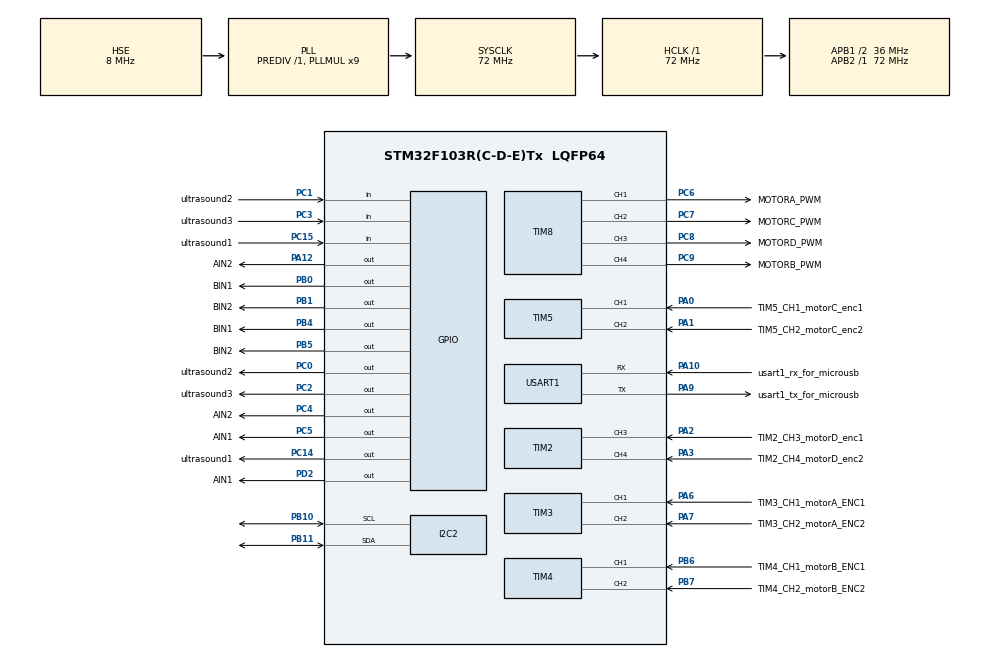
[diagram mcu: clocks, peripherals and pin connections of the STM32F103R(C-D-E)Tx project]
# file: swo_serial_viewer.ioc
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Mcu.Family=STM32F1
Mcu.Name=STM32F103R(C-D-E)Tx
Mcu.Package=LQFP64
NVIC.PriorityGroup=NVIC_PRIORITYGROUP_4
PA0-WKUP.GPIO_Label=TIM5_CH1_motorC_enc1
PA0-WKUP.Signal=S_TIM5_CH1
PA1.GPIO_Label=TIM5_CH2_motorC_enc2
PA1.Signal=S_TIM5_CH2
PA10.GPIO_Label=usart1_rx_for_microusb
PA10.Mode=Asynchronous
PA10.Signal=USART1_RX
PA12.GPIO_Label=AIN2
PA12.Signal=GPIO_Output
PA13.Mode=JTAG_4_pins
PA13.Signal=SYS_JTMS-SWDIO
PA14.Mode=JTAG_4_pins
PA14.Signal=SYS_JTCK-SWCLK
PA15.Mode=JTAG_4_pins
PA15.Signal=SYS_JTDI
PA2.GPIO_Label=TIM2_CH3_motorD_enc1
PA2.Signal=S_TIM2_CH3
PA3.GPIO_Label=TIM2_CH4_motorD_enc2
PA3.Signal=S_TIM2_CH4
PA6.GPIO_Label=TIM3_CH1_motorA_ENC1
PA6.Signal=S_TIM3_CH1
PA7.GPIO_Label=TIM3_CH2_motorA_ENC2
PA7.Signal=S_TIM3_CH2
PA9.GPIO_Label=usart1_tx_for_microusb
PA9.Mode=Asynchronous
PA9.Signal=USART1_TX
PB0.GPIO_Label=BIN1
PB0.Signal=GPIO_Output
PB1.GPIO_Label=BIN2
PB1.Signal=GPIO_Output
PB10.Mode=I2C
PB10.Signal=I2C2_SCL
PB11.Mode=I2C
PB11.Signal=I2C2_SDA
PB3.Mode=JTAG_4_pins
PB3.Signal=SYS_JTDO-TRACESWO
PB4.GPIO_Label=BIN1
PB4.Signal=GPIO_Output
PB5.GPIO_Label=BIN2
PB5.Signal=GPIO_Output
PB6.GPIO_Label=TIM4_CH1_motorB_ENC1
PB6.Signal=S_TIM4_CH1
PB7.GPIO_Label=TIM4_CH2_motorB_ENC2
PB7.Signal=S_TIM4_CH2
PC0.GPIO_Label=ultrasound2
PC0.Signal=GPIO_Output
PC1.GPIO_Label=ultrasound2
PC1.Signal=GPIO_Input
PC14-OSC32_IN.GPIO_Label=ultrasound1
PC14-OSC32_IN.Signal=GPIO_Output
PC15-OSC32_OUT.GPIO_Label=ultrasound1
PC15-OSC32_OUT.Signal=GPIO_Input
PC2.GPIO_Label=ultrasound3
PC2.Signal=GPIO_Output
PC3.GPIO_Label=ultrasound3
PC3.Signal=GPIO_Input
PC4.GPIO_Label=AIN2
PC4.Signal=GPIO_Output
PC5.GPIO_Label=AIN1
PC5.Signal=GPIO_Output
PC6.GPIO_Label=MOTORA_PWM
PC6.Signal=S_TIM8_CH1
PC7.GPIO_Label=MOTORC_PWM
PC7.Signal=S_TIM8_CH2
PC8.GPIO_Label=MOTORD_PWM
PC8.Signal=S_TIM8_CH3
PC9.GPIO_Label=MOTORB_PWM
PC9.Signal=S_TIM8_CH4
PD0-OSC_IN.Mode=HSE-External-Oscillator
PD0-OSC_IN.Signal=RCC_OSC_IN
PD1-OSC_OUT.Mode=HSE-External-Oscillator
PD1-OSC_OUT.Signal=RCC_OSC_OUT
PD2.GPIO_Label=AIN1
PD2.Signal=GPIO_Output
ProjectManager.HeapSize=0x200
ProjectManager.StackSize=0x400
ProjectManager.TargetToolchain=STM32CubeIDE
RCC.AHBFreq_Value=72000000
RCC.APB1CLKDivider=RCC_HCLK_DIV2
RCC.APB1Freq_Value=36000000
RCC.APB1TimFreq_Value=72000000
RCC.APB2Freq_Value=72000000
RCC.APB2TimFreq_Value=72000000
RCC.HCLKFreq_Value=72000000
RCC.PLLMUL=RCC_PLL_MUL9
RCC.PLLSourceVirtual=RCC_PLLSOURCE_HSE
RCC.SYSCLKFreq_VALUE=72000000
RCC.SYSCLKSource=RCC_SYSCLKSOURCE_PLLCLK
RCC.USBFreq_Value=72000000
SH.S_TIM2_CH3.0=TIM2_CH3,Input_Capture3_from_TI3
SH.S_TIM2_CH4.0=TIM2_CH4,Input_Capture4_from_TI4
SH.S_TIM3_CH1.0=TIM3_CH1,Input_Capture1_from_TI1
SH.S_TIM3_CH2.0=TIM3_CH2,Input_Capture2_from_TI2
SH.S_TIM4_CH1.0=TIM4_CH1,Input_Capture1_from_TI1
SH.S_TIM4_CH2.0=TIM4_CH2,Input_Capture2_from_TI2
SH.S_TIM5_CH1.0=TIM5_CH1,Input_Capture1_from_TI1
SH.S_TIM5_CH2.0=TIM5_CH2,Input_Capture2_from_TI2
SH.S_TIM8_CH1.0=TIM8_CH1,Output Compare1 CH1
SH.S_TIM8_CH2.0=TIM8_CH2,Output Compare2 CH2
SH.S_TIM8_CH3.0=TIM8_CH3,Output Compare3 CH3
SH.S_TIM8_CH4.0=TIM8_CH4,Output Compare4 CH4
TIM2.Channel-Input_Capture3_from_TI3=TIM_CHANNEL_3
TIM2.Channel-Input_Capture4_from_TI4=TIM_CHANNEL_4
TIM3.Channel-Input_Capture1_from_TI1=TIM_CHANNEL_1
TIM3.Channel-Input_Capture2_from_TI2=TIM_CHANNEL_2
TIM4.Channel-Input_Capture1_from_TI1=TIM_CHANNEL_1
TIM4.Channel-Input_Capture2_from_TI2=TIM_CHANNEL_2
TIM5.Channel-Input_Capture1_from_TI1=TIM_CHANNEL_1
TIM5.Channel-Input_Capture2_from_TI2=TIM_CHANNEL_2
TIM8.Channel-Output\ Compare1\ CH1=TIM_CHANNEL_1
TIM8.Channel-Output\ Compare2\ CH2=TIM_CHANNEL_2
TIM8.Channel-Output\ Compare3\ CH3=TIM_CHANNEL_3
TIM8.Channel-Output\ Compare4\ CH4=TIM_CHANNEL_4
USART1.VirtualMode=VM_ASYNC
board=custom

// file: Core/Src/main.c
/* USER CODE BEGIN Header */
/**
  ******************************************************************************
  * @file           : main.c
  * @brief          : Main program body
  ******************************************************************************
  * @attention
  *
  * <h2><center>&copy; Copyright (c) 2021 STMicroelectronics.
  * All rights reserved.</center></h2>
  *
  * This software component is licensed by ST under BSD 3-Clause license,
  * the "License"; You may not use this file except in compliance with the
  * License. You may obtain a copy of the License at:
  *                        opensource.org/licenses/BSD-3-Clause
  *
  ******************************************************************************
  */
/* USER CODE END Header */
#include "main.h"

I2C_HandleTypeDef hi2c2;

TIM_HandleTypeDef htim2;
TIM_HandleTypeDef htim3;
TIM_HandleTypeDef htim4;
TIM_HandleTypeDef htim5;
TIM_HandleTypeDef htim8;

UART_HandleTypeDef huart1;

void SystemClock_Config(void);
static void MX_GPIO_Init(void);
static void MX_I2C2_Init(void);
static void MX_TIM2_Init(void);
static void MX_TIM3_Init(void);
static void MX_TIM4_Init(void);
static void MX_TIM5_Init(void);
static void MX_TIM8_Init(void);
static void MX_USART1_UART_Init(void);

/* USER CODE BEGIN 0 */
int _write(int file, char *ptr, int len)
{
	int i=0;
	for(i=0; i<len; i++)
	{
		ITM_SendChar( (*ptr++) );
	}
	return len;
}

uint8_t count = 0;

/* USER CODE END 0 */

int main(void)
{

  /* MCU Configuration--------------------------------------------------------*/

  /* Reset of all peripherals, Initializes the Flash interface and the Systick. */
  HAL_Init();

  /* Configure the system clock */
  SystemClock_Config();

  /* Initialize all configured peripherals */
  MX_GPIO_Init();
  MX_I2C2_Init();
  MX_TIM2_Init();
  MX_TIM3_Init();
  MX_TIM4_Init();
  MX_TIM5_Init();
  MX_TIM8_Init();
  MX_USART1_UART_Init();

  /* Infinite loop */
  while (1)
  {

  }
}

void SystemClock_Config(void)
{
  RCC_OscInitTypeDef RCC_OscInitStruct = {0};
  RCC_ClkInitTypeDef RCC_ClkInitStruct = {0};

  /** Initializes the RCC Oscillators according to the specified parameters
  * in the RCC_OscInitTypeDef structure.
  */
  RCC_OscInitStruct.OscillatorType = RCC_OSCILLATORTYPE_HSE;
  RCC_OscInitStruct.HSEState = RCC_HSE_ON;
  RCC_OscInitStruct.HSEPredivValue = RCC_HSE_PREDIV_DIV1;
  RCC_OscInitStruct.HSIState = RCC_HSI_ON;
  RCC_OscInitStruct.PLL.PLLState = RCC_PLL_ON;
  RCC_OscInitStruct.PLL.PLLSource = RCC_PLLSOURCE_HSE;
  RCC_OscInitStruct.PLL.PLLMUL = RCC_PLL_MUL9;
  if (HAL_RCC_OscConfig(&RCC_OscInitStruct) != HAL_OK)
  {
    Error_Handler();
  }
  /** Initializes the CPU, AHB and APB buses clocks
  */
  RCC_ClkInitStruct.ClockType = RCC_CLOCKTYPE_HCLK|RCC_CLOCKTYPE_SYSCLK
                              |RCC_CLOCKTYPE_PCLK1|RCC_CLOCKTYPE_PCLK2;
  RCC_ClkInitStruct.SYSCLKSource = RCC_SYSCLKSOURCE_PLLCLK;
  RCC_ClkInitStruct.AHBCLKDivider = RCC_SYSCLK_DIV1;
  RCC_ClkInitStruct.APB1CLKDivider = RCC_HCLK_DIV2;
  RCC_ClkInitStruct.APB2CLKDivider = RCC_HCLK_DIV1;

  if (HAL_RCC_ClockConfig(&RCC_ClkInitStruct, FLASH_LATENCY_2) != HAL_OK)
  {
    Error_Handler();
  }
}

static void MX_I2C2_Init(void)
{

  hi2c2.Instance = I2C2;
  hi2c2.Init.ClockSpeed = 100000;
  hi2c2.Init.DutyCycle = I2C_DUTYCYCLE_2;
  hi2c2.Init.OwnAddress1 = 0;
  hi2c2.Init.AddressingMode = I2C_ADDRESSINGMODE_7BIT;
  hi2c2.Init.DualAddressMode = I2C_DUALADDRESS_DISABLE;
  hi2c2.Init.OwnAddress2 = 0;
  hi2c2.Init.GeneralCallMode = I2C_GENERALCALL_DISABLE;
  hi2c2.Init.NoStretchMode = I2C_NOSTRETCH_DISABLE;
  if (HAL_I2C_Init(&hi2c2) != HAL_OK)
  {
    Error_Handler();
  }

}

static void MX_TIM2_Init(void)
{

  TIM_MasterConfigTypeDef sMasterConfig = {0};
  TIM_IC_InitTypeDef sConfigIC = {0};

  htim2.Instance = TIM2;
  htim2.Init.Prescaler = 0;
  htim2.Init.CounterMode = TIM_COUNTERMODE_UP;
  htim2.Init.Period = 65535;
  htim2.Init.ClockDivision = TIM_CLOCKDIVISION_DIV1;
  htim2.Init.AutoReloadPreload = TIM_AUTORELOAD_PRELOAD_DISABLE;
  if (HAL_TIM_IC_Init(&htim2) != HAL_OK)
  {
    Error_Handler();
  }
  sMasterConfig.MasterOutputTrigger = TIM_TRGO_RESET;
  sMasterConfig.MasterSlaveMode = TIM_MASTERSLAVEMODE_DISABLE;
  if (HAL_TIMEx_MasterConfigSynchronization(&htim2, &sMasterConfig) != HAL_OK)
  {
    Error_Handler();
  }
  sConfigIC.ICPolarity = TIM_INPUTCHANNELPOLARITY_RISING;
  sConfigIC.ICSelection = TIM_ICSELECTION_DIRECTTI;
  sConfigIC.ICPrescaler = TIM_ICPSC_DIV1;
  sConfigIC.ICFilter = 0;
  if (HAL_TIM_IC_ConfigChannel(&htim2, &sConfigIC, TIM_CHANNEL_3) != HAL_OK)
  {
    Error_Handler();
  }
  if (HAL_TIM_IC_ConfigChannel(&htim2, &sConfigIC, TIM_CHANNEL_4) != HAL_OK)
  {
    Error_Handler();
  }

}

static void MX_TIM3_Init(void)
{

  TIM_MasterConfigTypeDef sMasterConfig = {0};
  TIM_IC_InitTypeDef sConfigIC = {0};

  htim3.Instance = TIM3;
  htim3.Init.Prescaler = 0;
  htim3.Init.CounterMode = TIM_COUNTERMODE_UP;
  htim3.Init.Period = 65535;
  htim3.Init.ClockDivision = TIM_CLOCKDIVISION_DIV1;
  htim3.Init.AutoReloadPreload = TIM_AUTORELOAD_PRELOAD_DISABLE;
  if (HAL_TIM_IC_Init(&htim3) != HAL_OK)
  {
    Error_Handler();
  }
  sMasterConfig.MasterOutputTrigger = TIM_TRGO_RESET;
  sMasterConfig.MasterSlaveMode = TIM_MASTERSLAVEMODE_DISABLE;
  if (HAL_TIMEx_MasterConfigSynchronization(&htim3, &sMasterConfig) != HAL_OK)
  {
    Error_Handler();
  }
  sConfigIC.ICPolarity = TIM_INPUTCHANNELPOLARITY_RISING;
  sConfigIC.ICSelection = TIM_ICSELECTION_DIRECTTI;
  sConfigIC.ICPrescaler = TIM_ICPSC_DIV1;
  sConfigIC.ICFilter = 0;
  if (HAL_TIM_IC_ConfigChannel(&htim3, &sConfigIC, TIM_CHANNEL_1) != HAL_OK)
  {
    Error_Handler();
  }
  if (HAL_TIM_IC_ConfigChannel(&htim3, &sConfigIC, TIM_CHANNEL_2) != HAL_OK)
  {
    Error_Handler();
  }

}

static void MX_TIM4_Init(void)
{

  TIM_MasterConfigTypeDef sMasterConfig = {0};
  TIM_IC_InitTypeDef sConfigIC = {0};

  htim4.Instance = TIM4;
  htim4.Init.Prescaler = 0;
  htim4.Init.CounterMode = TIM_COUNTERMODE_UP;
  htim4.Init.Period = 65535;
  htim4.Init.ClockDivision = TIM_CLOCKDIVISION_DIV1;
  htim4.Init.AutoReloadPreload = TIM_AUTORELOAD_PRELOAD_DISABLE;
  if (HAL_TIM_IC_Init(&htim4) != HAL_OK)
  {
    Error_Handler();
  }
  sMasterConfig.MasterOutputTrigger = TIM_TRGO_RESET;
  sMasterConfig.MasterSlaveMode = TIM_MASTERSLAVEMODE_DISABLE;
  if (HAL_TIMEx_MasterConfigSynchronization(&htim4, &sMasterConfig) != HAL_OK)
  {
    Error_Handler();
  }
  sConfigIC.ICPolarity = TIM_INPUTCHANNELPOLARITY_RISING;
  sConfigIC.ICSelection = TIM_ICSELECTION_DIRECTTI;
  sConfigIC.ICPrescaler = TIM_ICPSC_DIV1;
  sConfigIC.ICFilter = 0;
  if (HAL_TIM_IC_ConfigChannel(&htim4, &sConfigIC, TIM_CHANNEL_1) != HAL_OK)
  {
    Error_Handler();
  }
  if (HAL_TIM_IC_ConfigChannel(&htim4, &sConfigIC, TIM_CHANNEL_2) != HAL_OK)
  {
    Error_Handler();
  }

}

static void MX_TIM5_Init(void)
{

  TIM_MasterConfigTypeDef sMasterConfig = {0};
  TIM_IC_InitTypeDef sConfigIC = {0};

  htim5.Instance = TIM5;
  htim5.Init.Prescaler = 0;
  htim5.Init.CounterMode = TIM_COUNTERMODE_UP;
  htim5.Init.Period = 65535;
  htim5.Init.ClockDivision = TIM_CLOCKDIVISION_DIV1;
  htim5.Init.AutoReloadPreload = TIM_AUTORELOAD_PRELOAD_DISABLE;
  if (HAL_TIM_IC_Init(&htim5) != HAL_OK)
  {
    Error_Handler();
  }
  sMasterConfig.MasterOutputTrigger = TIM_TRGO_RESET;
  sMasterConfig.MasterSlaveMode = TIM_MASTERSLAVEMODE_DISABLE;
  if (HAL_TIMEx_MasterConfigSynchronization(&htim5, &sMasterConfig) != HAL_OK)
  {
    Error_Handler();
  }
  sConfigIC.ICPolarity = TIM_INPUTCHANNELPOLARITY_RISING;
  sConfigIC.ICSelection = TIM_ICSELECTION_DIRECTTI;
  sConfigIC.ICPrescaler = TIM_ICPSC_DIV1;
  sConfigIC.ICFilter = 0;
  if (HAL_TIM_IC_ConfigChannel(&htim5, &sConfigIC, TIM_CHANNEL_1) != HAL_OK)
  {
    Error_Handler();
  }
  if (HAL_TIM_IC_ConfigChannel(&htim5, &sConfigIC, TIM_CHANNEL_2) != HAL_OK)
  {
    Error_Handler();
  }

}

static void MX_TIM8_Init(void)
{

  TIM_MasterConfigTypeDef sMasterConfig = {0};
  TIM_OC_InitTypeDef sConfigOC = {0};
  TIM_BreakDeadTimeConfigTypeDef sBreakDeadTimeConfig = {0};

  htim8.Instance = TIM8;
  htim8.Init.Prescaler = 0;
  htim8.Init.CounterMode = TIM_COUNTERMODE_UP;
  htim8.Init.Period = 65535;
  htim8.Init.ClockDivision = TIM_CLOCKDIVISION_DIV1;
  htim8.Init.RepetitionCounter = 0;
  htim8.Init.AutoReloadPreload = TIM_AUTORELOAD_PRELOAD_DISABLE;
  if (HAL_TIM_OC_Init(&htim8) != HAL_OK)
  {
    Error_Handler();
  }
  sMasterConfig.MasterOutputTrigger = TIM_TRGO_RESET;
  sMasterConfig.MasterSlaveMode = TIM_MASTERSLAVEMODE_DISABLE;
  if (HAL_TIMEx_MasterConfigSynchronization(&htim8, &sMasterConfig) != HAL_OK)
  {
    Error_Handler();
  }
  sConfigOC.OCMode = TIM_OCMODE_TIMING;
  sConfigOC.Pulse = 0;
  sConfigOC.OCPolarity = TIM_OCPOLARITY_HIGH;
  sConfigOC.OCNPolarity = TIM_OCNPOLARITY_HIGH;
  sConfigOC.OCFastMode = TIM_OCFAST_DISABLE;
  sConfigOC.OCIdleState = TIM_OCIDLESTATE_RESET;
  sConfigOC.OCNIdleState = TIM_OCNIDLESTATE_RESET;
  if (HAL_TIM_OC_ConfigChannel(&htim8, &sConfigOC, TIM_CHANNEL_1) != HAL_OK)
  {
    Error_Handler();
  }
  if (HAL_TIM_OC_ConfigChannel(&htim8, &sConfigOC, TIM_CHANNEL_2) != HAL_OK)
  {
    Error_Handler();
  }
  if (HAL_TIM_OC_ConfigChannel(&htim8, &sConfigOC, TIM_CHANNEL_3) != HAL_OK)
  {
    Error_Handler();
  }
  if (HAL_TIM_OC_ConfigChannel(&htim8, &sConfigOC, TIM_CHANNEL_4) != HAL_OK)
  {
    Error_Handler();
  }
  sBreakDeadTimeConfig.OffStateRunMode = TIM_OSSR_DISABLE;
  sBreakDeadTimeConfig.OffStateIDLEMode = TIM_OSSI_DISABLE;
  sBreakDeadTimeConfig.LockLevel = TIM_LOCKLEVEL_OFF;
  sBreakDeadTimeConfig.DeadTime = 0;
  sBreakDeadTimeConfig.BreakState = TIM_BREAK_DISABLE;
  sBreakDeadTimeConfig.BreakPolarity = TIM_BREAKPOLARITY_HIGH;
  sBreakDeadTimeConfig.AutomaticOutput = TIM_AUTOMATICOUTPUT_DISABLE;
  if (HAL_TIMEx_ConfigBreakDeadTime(&htim8, &sBreakDeadTimeConfig) != HAL_OK)
  {
    Error_Handler();
  }
  HAL_TIM_MspPostInit(&htim8);

}

static void MX_USART1_UART_Init(void)
{

  huart1.Instance = USART1;
  huart1.Init.BaudRate = 115200;
  huart1.Init.WordLength = UART_WORDLENGTH_8B;
  huart1.Init.StopBits = UART_STOPBITS_1;
  huart1.Init.Parity = UART_PARITY_NONE;
  huart1.Init.Mode = UART_MODE_TX_RX;
  huart1.Init.HwFlowCtl = UART_HWCONTROL_NONE;
  huart1.Init.OverSampling = UART_OVERSAMPLING_16;
  if (HAL_UART_Init(&huart1) != HAL_OK)
  {
    Error_Handler();
  }

}

static void MX_GPIO_Init(void)
{
  GPIO_InitTypeDef GPIO_InitStruct = {0};

  /* GPIO Ports Clock Enable */
  __HAL_RCC_GPIOC_CLK_ENABLE();
  __HAL_RCC_GPIOD_CLK_ENABLE();
  __HAL_RCC_GPIOA_CLK_ENABLE();
  __HAL_RCC_GPIOB_CLK_ENABLE();

  /*Configure GPIO pin Output Level */
  HAL_GPIO_WritePin(GPIOC, ultrasound1_Pin|ultrasound2_Pin|ultrasound3_Pin|AIN2_Pin
                          |AIN1_Pin, GPIO_PIN_RESET);

  /*Configure GPIO pin Output Level */
  HAL_GPIO_WritePin(GPIOB, BIN1_Pin|BIN2_Pin|BIN1B4_Pin|BIN2B5_Pin, GPIO_PIN_RESET);

  /*Configure GPIO pin Output Level */
  HAL_GPIO_WritePin(AIN2A12_GPIO_Port, AIN2A12_Pin, GPIO_PIN_RESET);

  /*Configure GPIO pin Output Level */
  HAL_GPIO_WritePin(AIN1D2_GPIO_Port, AIN1D2_Pin, GPIO_PIN_RESET);

  /*Configure GPIO pins : PC13 PC10 PC11 PC12 */
  GPIO_InitStruct.Pin = GPIO_PIN_13|GPIO_PIN_10|GPIO_PIN_11|GPIO_PIN_12;
  GPIO_InitStruct.Mode = GPIO_MODE_ANALOG;
  HAL_GPIO_Init(GPIOC, &GPIO_InitStruct);

  /*Configure GPIO pins : ultrasound1_Pin ultrasound2_Pin ultrasound3_Pin AIN2_Pin
                           AIN1_Pin */
  GPIO_InitStruct.Pin = ultrasound1_Pin|ultrasound2_Pin|ultrasound3_Pin|AIN2_Pin
                          |AIN1_Pin;
  GPIO_InitStruct.Mode = GPIO_MODE_OUTPUT_PP;
  GPIO_InitStruct.Pull = GPIO_NOPULL;
  GPIO_InitStruct.Speed = GPIO_SPEED_FREQ_LOW;
  HAL_GPIO_Init(GPIOC, &GPIO_InitStruct);

  /*Configure GPIO pins : ultrasound1C15_Pin ultrasound2C1_Pin ultrasound3C3_Pin */
  GPIO_InitStruct.Pin = ultrasound1C15_Pin|ultrasound2C1_Pin|ultrasound3C3_Pin;
  GPIO_InitStruct.Mode = GPIO_MODE_INPUT;
  GPIO_InitStruct.Pull = GPIO_NOPULL;
  HAL_GPIO_Init(GPIOC, &GPIO_InitStruct);

  /*Configure GPIO pins : PA4 PA5 PA8 PA11 */
  GPIO_InitStruct.Pin = GPIO_PIN_4|GPIO_PIN_5|GPIO_PIN_8|GPIO_PIN_11;
  GPIO_InitStruct.Mode = GPIO_MODE_ANALOG;
  HAL_GPIO_Init(GPIOA, &GPIO_InitStruct);

  /*Configure GPIO pins : BIN1_Pin BIN2_Pin BIN1B4_Pin BIN2B5_Pin */
  GPIO_InitStruct.Pin = BIN1_Pin|BIN2_Pin|BIN1B4_Pin|BIN2B5_Pin;
  GPIO_InitStruct.Mode = GPIO_MODE_OUTPUT_PP;
  GPIO_InitStruct.Pull = GPIO_NOPULL;
  GPIO_InitStruct.Speed = GPIO_SPEED_FREQ_LOW;
  HAL_GPIO_Init(GPIOB, &GPIO_InitStruct);

  /*Configure GPIO pins : PB2 PB12 PB13 PB14
                           PB15 PB8 PB9 */
  GPIO_InitStruct.Pin = GPIO_PIN_2|GPIO_PIN_12|GPIO_PIN_13|GPIO_PIN_14
                          |GPIO_PIN_15|GPIO_PIN_8|GPIO_PIN_9;
  GPIO_InitStruct.Mode = GPIO_MODE_ANALOG;
  HAL_GPIO_Init(GPIOB, &GPIO_InitStruct);

  /*Configure GPIO pin : AIN2A12_Pin */
  GPIO_InitStruct.Pin = AIN2A12_Pin;
  GPIO_InitStruct.Mode = GPIO_MODE_OUTPUT_PP;
  GPIO_InitStruct.Pull = GPIO_NOPULL;
  GPIO_InitStruct.Speed = GPIO_SPEED_FREQ_LOW;
  HAL_GPIO_Init(AIN2A12_GPIO_Port, &GPIO_InitStruct);

  /*Configure GPIO pin : AIN1D2_Pin */
  GPIO_InitStruct.Pin = AIN1D2_Pin;
  GPIO_InitStruct.Mode = GPIO_MODE_OUTPUT_PP;
  GPIO_InitStruct.Pull = GPIO_NOPULL;
  GPIO_InitStruct.Speed = GPIO_SPEED_FREQ_LOW;
  HAL_GPIO_Init(AIN1D2_GPIO_Port, &GPIO_InitStruct);

}

void Error_Handler(void)
{
}

/************************ (C) COPYRIGHT STMicroelectronics *****END OF FILE****/
